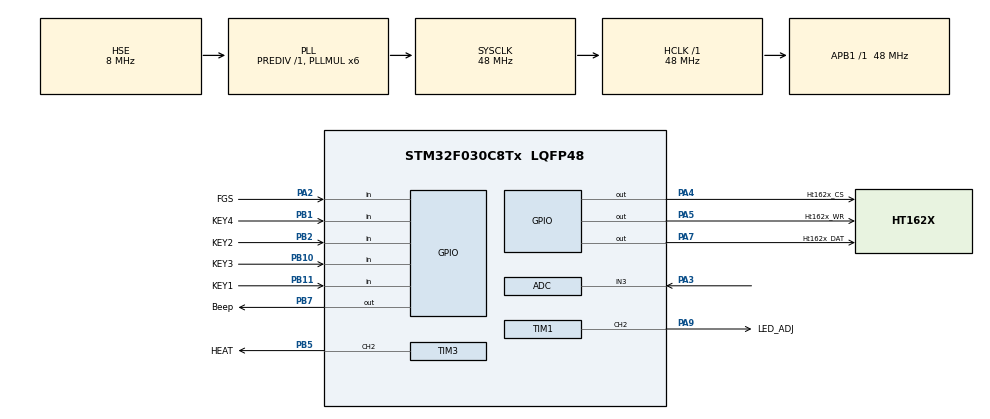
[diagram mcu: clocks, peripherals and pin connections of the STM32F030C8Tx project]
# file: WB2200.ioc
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ADC.DMAContinuousRequests=ENABLE
ADC.EnableAnalogWatchDog=false
ADC.ExternalTrigConv=ADC_EXTERNALTRIGCONV_T15_TRGO
ADC.SamplingTime=ADC_SAMPLETIME_239CYCLES_5
Dma.ADC.0.Direction=DMA_PERIPH_TO_MEMORY
Dma.ADC.0.Instance=DMA1_Channel1
Dma.ADC.0.MemDataAlignment=DMA_MDATAALIGN_HALFWORD
Dma.ADC.0.MemInc=DMA_MINC_ENABLE
Dma.ADC.0.Mode=DMA_CIRCULAR
Dma.ADC.0.PeriphDataAlignment=DMA_PDATAALIGN_HALFWORD
Dma.ADC.0.PeriphInc=DMA_PINC_DISABLE
Dma.ADC.0.Priority=DMA_PRIORITY_HIGH
Dma.Request0=ADC
Mcu.Family=STM32F0
Mcu.Name=STM32F030C8Tx
Mcu.Package=LQFP48
NVIC.ADC1_IRQn=true\:0\:0\:false\:false\:true\:true\:true\:true
NVIC.DMA1_Channel1_IRQn=true\:0\:0\:false\:false\:true\:false\:true\:true
PA13.Mode=Serial_Wire
PA13.Signal=SYS_SWDIO
PA14.Mode=Serial_Wire
PA14.Signal=SYS_SWCLK
PA2.GPIO_Label=FGS
PA2.Signal=GPIO_Input
PA3.Mode=IN3
PA3.Signal=ADC_IN3
PA4.GPIO_Label=Ht162x_CS
PA4.GPIO_ModeDefaultOutputPP=GPIO_MODE_OUTPUT_PP
PA4.GPIO_PuPd=GPIO_PULLUP
PA4.GPIO_Speed=GPIO_SPEED_FREQ_HIGH
PA4.PinState=GPIO_PIN_SET
PA4.Signal=GPIO_Output
PA5.GPIO_Label=Ht162x_WR
PA5.GPIO_PuPd=GPIO_PULLUP
PA5.GPIO_Speed=GPIO_SPEED_FREQ_HIGH
PA5.PinState=GPIO_PIN_SET
PA5.Signal=GPIO_Output
PA7.GPIO_Label=Ht162x_DAT
PA7.GPIO_PuPd=GPIO_PULLUP
PA7.GPIO_Speed=GPIO_SPEED_FREQ_HIGH
PA7.PinState=GPIO_PIN_SET
PA7.Signal=GPIO_Output
PA9.GPIO_Label=LED_ADJ
PA9.Signal=S_TIM1_CH2
PB1.GPIO_Label=KEY4
PB1.Signal=GPIO_Input
PB10.GPIO_Label=KEY3
PB10.Signal=GPIO_Input
PB11.GPIO_Label=KEY1
PB11.Signal=GPIO_Input
PB2.GPIO_Label=KEY2
PB2.Signal=GPIO_Input
PB5.GPIO_Label=HEAT
PB5.Signal=S_TIM3_CH2
PB7.GPIO_Label=Beep
PB7.Signal=GPIO_Output
PF0-OSC_IN.Mode=HSE-External-Oscillator
PF0-OSC_IN.Signal=RCC_OSC_IN
PF1-OSC_OUT.Mode=HSE-External-Oscillator
PF1-OSC_OUT.Signal=RCC_OSC_OUT
ProjectManager.HeapSize=0x200
ProjectManager.StackSize=0x400
ProjectManager.TargetToolchain=MDK-ARM V5.32
RCC.AHBFreq_Value=48000000
RCC.APB1Freq_Value=48000000
RCC.APB1TimFreq_Value=48000000
RCC.HCLKFreq_Value=48000000
RCC.PLLMUL=RCC_PLL_MUL6
RCC.PLLSourceVirtual=RCC_PLLSOURCE_HSE
RCC.SYSCLKFreq_VALUE=48000000
RCC.SYSCLKSource=RCC_SYSCLKSOURCE_PLLCLK
SH.S_TIM1_CH2.0=TIM1_CH2,PWM Generation2 CH2
SH.S_TIM3_CH2.0=TIM3_CH2,PWM Generation2 CH2
TIM1.Channel-PWM\ Generation2\ CH2=TIM_CHANNEL_2
TIM1.Period=200-1
TIM1.Prescaler=12-1
TIM15.Period=1000-1
TIM15.Prescaler=48-1
TIM15.TIM_MasterOutputTrigger=TIM_TRGO_UPDATE
TIM3.Channel-PWM\ Generation2\ CH2=TIM_CHANNEL_2
TIM3.Period=200-1
TIM3.Prescaler=12-1
VP_TIM15_VS_ClockSourceINT.Mode=Internal
board=custom

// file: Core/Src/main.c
/* USER CODE BEGIN Header */
/**
  ******************************************************************************
  * @file           : main.c
  * @brief          : Main program body
  ******************************************************************************
  * @attention
  *
  * Copyright (c) 2024 STMicroelectronics.
  * All rights reserved.
  *
  * This software is licensed under terms that can be found in the LICENSE file
  * in the root directory of this software component.
  * If no LICENSE file comes with this software, it is provided AS-IS.
  *
  ******************************************************************************
  */
/* USER CODE END Header */
#include "main.h"
#include "adc.h"
#include "dma.h"
#include "tim.h"
#include "gpio.h"

void SystemClock_Config(void);

int main(void)
{

  /* MCU Configuration--------------------------------------------------------*/

  /* Reset of all peripherals, Initializes the Flash interface and the Systick. */
  HAL_Init();

  /* Configure the system clock */
  SystemClock_Config();

  /* Initialize all configured peripherals */
  MX_GPIO_Init();
  MX_DMA_Init();
  MX_ADC_Init();
  MX_TIM3_Init();
  MX_TIM15_Init();
  MX_TIM1_Init();
  /* USER CODE BEGIN 2 */
    System_Init();//ϵͳ������ʼ��
    //SEGGER_RTT_ConfigUpBuffer(1, "JScope_i2", NULL, 4096, SEGGER_RTT_MODE_NO_BLOCK_SKIP);
  /* USER CODE END 2 */

  /* Infinite loop */
  /* USER CODE BEGIN WHILE */
  while (1)
  {
//      printf("%d",Temp.Rel);
	  Show_Display();
    /* USER CODE END WHILE */

  }
}

void SystemClock_Config(void)
{
  RCC_OscInitTypeDef RCC_OscInitStruct = {0};
  RCC_ClkInitTypeDef RCC_ClkInitStruct = {0};

  /** Initializes the RCC Oscillators according to the specified parameters
  * in the RCC_OscInitTypeDef structure.
  */
  RCC_OscInitStruct.OscillatorType = RCC_OSCILLATORTYPE_HSI14|RCC_OSCILLATORTYPE_HSE;
  RCC_OscInitStruct.HSEState = RCC_HSE_ON;
  RCC_OscInitStruct.HSI14State = RCC_HSI14_ON;
  RCC_OscInitStruct.HSI14CalibrationValue = 16;
  RCC_OscInitStruct.PLL.PLLState = RCC_PLL_ON;
  RCC_OscInitStruct.PLL.PLLSource = RCC_PLLSOURCE_HSE;
  RCC_OscInitStruct.PLL.PLLMUL = RCC_PLL_MUL6;
  RCC_OscInitStruct.PLL.PREDIV = RCC_PREDIV_DIV1;
  if (HAL_RCC_OscConfig(&RCC_OscInitStruct) != HAL_OK)
  {
    Error_Handler();
  }

  /** Initializes the CPU, AHB and APB buses clocks
  */
  RCC_ClkInitStruct.ClockType = RCC_CLOCKTYPE_HCLK|RCC_CLOCKTYPE_SYSCLK
                              |RCC_CLOCKTYPE_PCLK1;
  RCC_ClkInitStruct.SYSCLKSource = RCC_SYSCLKSOURCE_PLLCLK;
  RCC_ClkInitStruct.AHBCLKDivider = RCC_SYSCLK_DIV1;
  RCC_ClkInitStruct.APB1CLKDivider = RCC_HCLK_DIV1;

  if (HAL_RCC_ClockConfig(&RCC_ClkInitStruct, FLASH_LATENCY_1) != HAL_OK)
  {
    Error_Handler();
  }
}

void Error_Handler(void)
{
  __disable_irq();
  while (1)
  {
  }
}
